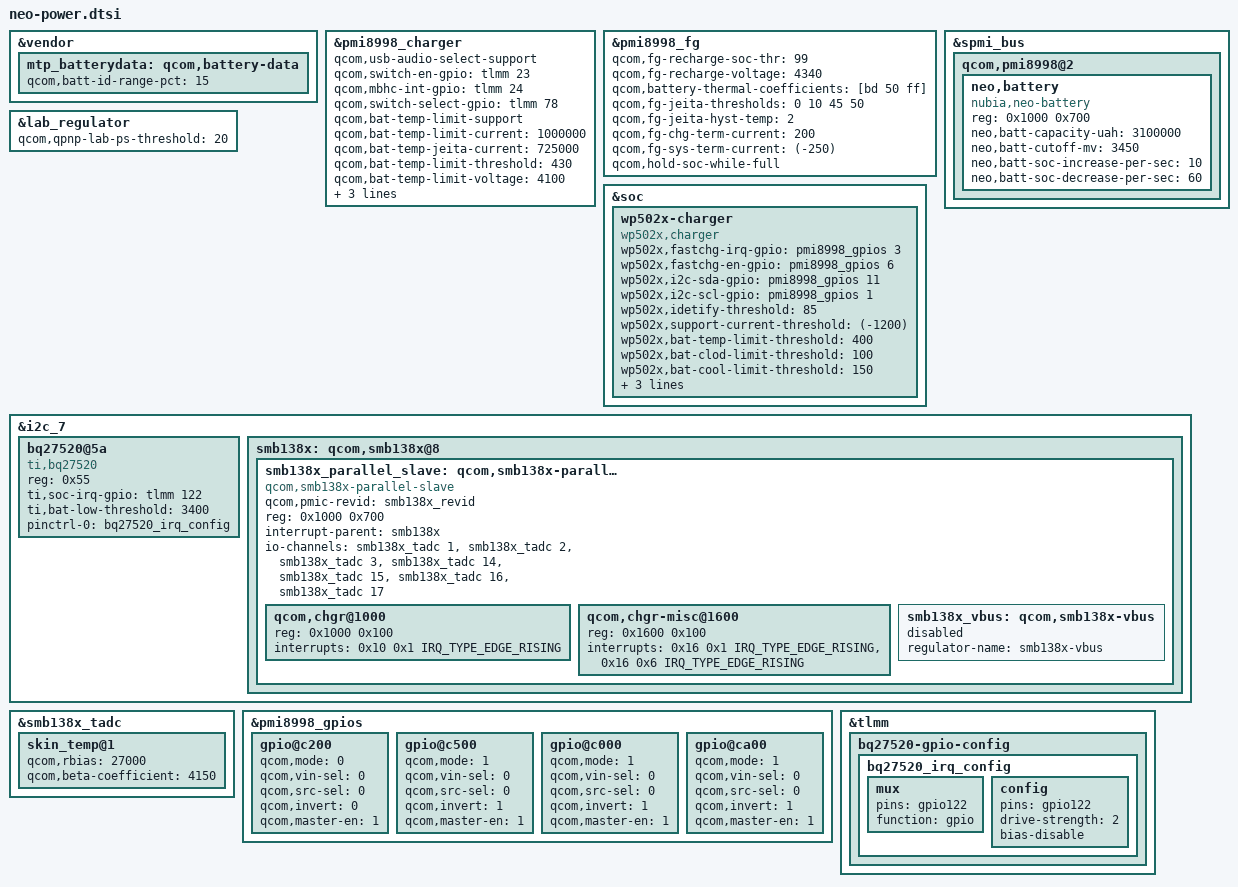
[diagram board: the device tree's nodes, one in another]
/*
 * Copyright (c) 2015-2016, The Linux Foundation. All rights reserved.
 *
 * This program is free software; you can redistribute it and/or modify
 * it under the terms of the GNU General Public License version 2 and
 * only version 2 as published by the Free Software Foundation.
 *
 * This program is distributed in the hope that it will be useful,
 * but WITHOUT ANY WARRANTY; without even the implied warranty of
 * MERCHANTABILITY or FITNESS FOR A PARTICULAR PURPOSE.  See the
 * GNU General Public License for more details.
 */

/* Copyright (c) 2014, The Linux Foundation. All rights reserved.
 *
 * This program is free software; you can redistribute it and/or modify
 * it under the terms of the GNU General Public License version 2 and
 * only version 2 as published by the Free Software Foundation.
 *
 * This program is distributed in the hope that it will be useful,
 * but WITHOUT ANY WARRANTY; without even the implied warranty of
 * MERCHANTABILITY or FITNESS FOR A PARTICULAR PURPOSE.  See the
 * GNU General Public License for more details.
 */

&vendor {
	/delete-node/ qcom,battery-data;

	mtp_batterydata: qcom,battery-data {
		qcom,batt-id-range-pct = <15>;
	#include "fg-gen3-batterydata-scud-3200mah.dtsi"
	};
};

//msm-pmi8998.dtsi
&pmi8998_charger {
	/*BEGIN:Modify for usb/audio switch */
	qcom,usb-audio-select-support;
	qcom,switch-en-gpio = <&tlmm 23 0>;
	qcom,mbhc-int-gpio = <&tlmm 24 0>;
	qcom,switch-select-gpio = <&tlmm 78 0>;

	qcom,bat-temp-limit-support;
	qcom,bat-temp-limit-current = <1000000>;
	qcom,bat-temp-jeita-current = <725000>;
	qcom,bat-temp-limit-threshold = <430>;
	qcom,bat-temp-limit-voltage = <4100>;
	/*END*/

	qcom,fcc-max-ua = <2000000>;
	qcom,fv-max-uv = <4400000>;
	qcom,usb-icl-ua = <2000000>;
};

&pmi8998_fg {
	qcom,fg-recharge-soc-thr = <99>;
	qcom,fg-recharge-voltage = <4340>;
	qcom,battery-thermal-coefficients = [bd 50 ff];
	qcom,fg-jeita-thresholds = <0 10 45 50>;
	qcom,fg-jeita-hyst-temp = <2>;
	qcom,fg-chg-term-current = <200>;
	qcom,fg-sys-term-current = <(-250)>;
	qcom,hold-soc-while-full;
};

&spmi_bus {
	qcom,pmi8998@2 {
		neo,battery {
			compatible = "nubia,neo-battery";
			#address-cells = <1>;
			#size-cells = <1>;
			reg = <0x1000 0x700>;
			neo,batt-capacity-uah = <3100000>;
			neo,batt-cutoff-mv = <3450>;
			neo,batt-soc-increase-per-sec = <10>;
			neo,batt-soc-decrease-per-sec = <60>;
		};
	};
};

&lab_regulator {
	qcom,qpnp-lab-ps-threshold = <20>;
};
//msm-pmi8998.dtsi End

&soc {
	wp502x-charger {
		compatible = "wp502x,charger";
		wp502x,fastchg-irq-gpio = <&pmi8998_gpios 3 0x00>;
		wp502x,fastchg-en-gpio = <&pmi8998_gpios 6 0x00>;
		wp502x,i2c-sda-gpio = <&pmi8998_gpios 11 0x00>;
		wp502x,i2c-scl-gpio = <&pmi8998_gpios 1 0x00>;
		wp502x,idetify-threshold = <85>;
		wp502x,support-current-threshold = <(-1200)>;
		wp502x,bat-temp-limit-threshold = <400>;
		wp502x,bat-clod-limit-threshold = <100>;
		wp502x,bat-cool-limit-threshold = <150>;
		wp502x,bat-hot-limit-threshold = <440>;
		wp502x,fastchg-max-ma = <5000>;
		wp502x,vref1p8-en-gpio = <&tlmm 51 0>;
	};
};

&i2c_7 {
	bq27520@5a{
		compatible = "ti,bq27520";
		reg = <0x55>;
		ti,soc-irq-gpio = <&tlmm 122 0x00>;
		ti,bat-low-threshold = <3400>;
		pinctrl-names = "irq_config";
		pinctrl-0 = <&bq27520_irq_config>;
	};
	
	smb138x: qcom,smb138x@8 {
		#size-cells = <1>;

		/delete-node/ qcom,smb1381-charger@1000;
		
		smb138x_parallel_slave: qcom,smb138x-parallel-slave@1000 {
			compatible = "qcom,smb138x-parallel-slave";
			qcom,pmic-revid = <&smb138x_revid>;
			reg = <0x1000 0x700>;
			#address-cells = <1>;
			#size-cells = <1>;
			interrupt-parent = <&smb138x>;
			io-channels =
				<&smb138x_tadc 1>,
				<&smb138x_tadc 2>,
				<&smb138x_tadc 3>,
				<&smb138x_tadc 14>,
				<&smb138x_tadc 15>,
				<&smb138x_tadc 16>,
				<&smb138x_tadc 17>;
			io-channel-names =
				"connector_temp",
				"charger_temp",
				"batt_i",
				"connector_temp_thr1",
				"connector_temp_thr2",
				"connector_temp_thr3",
				"charger_temp_max";

			qcom,chgr@1000 {
				reg = <0x1000 0x100>;
				interrupts = <0x10 0x1 IRQ_TYPE_EDGE_RISING>;
				interrupt-names = "chg-state-change";
			};

			qcom,chgr-misc@1600 {
				reg = <0x1600 0x100>;
				interrupts = <0x16 0x1 IRQ_TYPE_EDGE_RISING>,
					     <0x16 0x6 IRQ_TYPE_EDGE_RISING>;
				interrupt-names = "wdog-bark",
						  "temperature-change";
			};
		};
	};
};

	
&smb138x_parallel_slave {
	smb138x_vbus: qcom,smb138x-vbus {
		status = "disabled";
		regulator-name = "smb138x-vbus";
	};
};


&smb138x_tadc {
	skin_temp@1 {
		qcom,rbias = <27000>;
		qcom,beta-coefficient = <4150>;
	};
};

&pmi8998_gpios {
	/* GPIO 3 for direct charger irq signal */
	gpio@c200 {
		status = "okay";
		qcom,mode = <0>;
		qcom,vin-sel = <0>;
		qcom,src-sel = <0>;
		qcom,invert = <0>;
		qcom,master-en = <1>;
	};
	/* GPIO 6 for direct charger control signal */
	gpio@c500 {
		/delete-property/ qcom,pull;
		/delete-property/ qcom,out-strength;

		status = "okay";
		qcom,mode = <1>;
		qcom,vin-sel = <0>;
		qcom,src-sel = <0>;
		qcom,invert = <1>;
		qcom,master-en = <1>;
	};
	/* GPIO 1 for direct charger i2c scl signal */
	gpio@c000 {
		status = "okay";
		qcom,mode = <1>;
		qcom,vin-sel = <0>;
		qcom,src-sel = <0>;
		qcom,invert = <1>;
		qcom,master-en = <1>;
	};
	/* GPIO 11 for direct charger i2c sda signal */
	gpio@ca00 {
		status = "okay";
		qcom,mode = <1>;
		qcom,vin-sel = <0>;
		qcom,src-sel = <0>;
		qcom,invert = <1>;
		qcom,master-en = <1>;
	};
};

&tlmm {
	bq27520-gpio-config {
        bq27520_irq_config: bq27520_irq_config {
			mux {
				pins = "gpio122";
				function = "gpio";
			};

			config {
				pins = "gpio122";
				drive-strength = <2>;
				bias-disable;
			};
		};
	};
};
